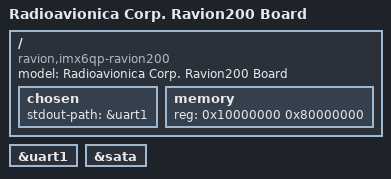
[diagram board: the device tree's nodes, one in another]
/*
 */

/dts-v1/;

#include <arm/imx6qp.dtsi>
#include <dt-bindings/input/input.h>
#include <dt-bindings/gpio/gpio.h>

#include "imx6qdl-ravion-v2.dtsi"

/ {
	model = "Radioavionica Corp. Ravion200 Board";
	compatible = "ravion,imx6qp-ravion200", "fsl,imx6qp";

	chosen {
		stdout-path = &uart1;
	};


	memory {
		reg = <0x10000000 0x80000000>;
	};
	
};

&uart1 {	status = "okay";	};
&sata {		status = "okay";	};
